# I3C0_WRAP_CORE_VBP_MST register map
Vendor: Texas Instruments
Peripheral module from a debugger description file (folder J7ES).
Registers are 32-bit, read-write, reset 0x0 unless marked. A register's access mark holds for its fields unless they carry their own. Offsets are as the file gives them; lines under a group give offsets from that group; [hi:lo] are bit positions; {n}, {i} and the like mark numbered series; 'fields as' and 'values as' point back to an identical list; <NAME> marks a mode.

## I3C0_WRAP_CORE_VBP_MST (part 1 of 2)
0x00 I3C_DEV_ID ro reset 0x5034 — This register holds the IP identifier.
  [15:0] DEV_ID — Unique IP identifier within IP portfolio
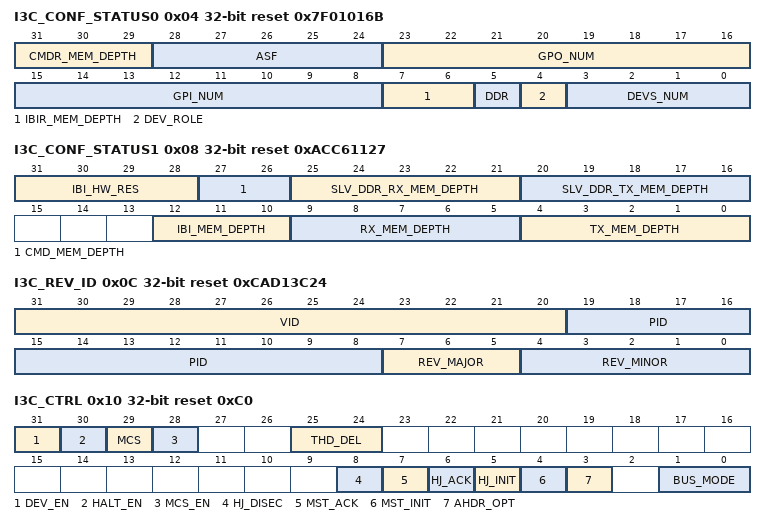
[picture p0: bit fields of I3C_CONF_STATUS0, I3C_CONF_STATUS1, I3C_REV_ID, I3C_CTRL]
0x04 I3C_CONF_STATUS0 ro reset 0x7F01016B — The read-only Configuration Status Register 0 indicates the hardware configuration options chosen for implementation of the I3C-Master.
  [31:29] CMDR_MEM_DEPTH — CMD Resp MEM depth coded into 3 bits
  [28:24] ASF — Indicates supported ASF checks
  [23:16] GPO_NUM — Returns the value of User GPO [1-126]
  [15:8] GPI_NUM — Returns the value of User GPI [1-126]
  [7:6] IBIR_MEM_DEPTH — IBI Resp MEM depth coded into 2 bits
  [5] DDR — Indicates if DDR is supported
  [4] DEV_ROLE — Returns status of Device Role [Main/Secondary Master]
  [3:0] DEVS_NUM — Returns the number of retaining registers for I3C Slave devices [Addresses and Characteristics], the max value is 11
0x08 I3C_CONF_STATUS1 ro reset 0xACC61127 — The read-only Configuration Status Register 1 indicates the hardware configuration options chosen for implementation of the I3C-Master.
  [31:28] IBI_HW_RES — IBI resources
  [27:26] CMD_MEM_DEPTH — CMD FIFO depth coded into 3 bits
  [25:21] SLV_DDR_RX_MEM_DEPTH — SLV DDR RX FIFO depth coded into 5 bits
  [20:16] SLV_DDR_TX_MEM_DEPTH — SLV DDR TX FIFO depth coded into 5 bits
  [12:10] IBI_MEM_DEPTH — IBI FIFO depth coded into 3 bits
  [9:5] RX_MEM_DEPTH — RX FIFO depth coded into 5 bits
  [4:0] TX_MEM_DEPTH — TX FIFO depth coded into 5 bits
0x0C I3C_REV_ID ro reset 0xCAD13C24 — This register gives an information about particular version of the IP.
  [31:20] VID — VENDOR_ID: IP vendor ID affected to IP [reset = 0xCAD]
  [19:8] PID — PRODUCT_ID: unique IP identifier within IP portfolio [reset = 0x13C]
  [7:5] REV_MAJOR — X: Major revision value
  [4:0] REV_MINOR — Y: Minor revision value
0x10 I3C_CTRL access per field reset 0xC0 — Control Register for I3C Master IP - register that provides main control and configuration options for the controller.
  [31] DEV_EN rw — When set HIGH the I3C-Master is enabled and it can initiates the I3C/I2C transactions Also write access to the following fields of various registers is forbidden : CTRLbus_mode CTRLahdr_opt CTRLhalt_en PRESCL_CTRL0i3c PRESCL_CTRL0i2c PRESCL_CTRL1od_low PRESCL_CTRL1pp_low When set LOW the I3C-Master is disabled and access to the key control fields that listed above is available If this bit is being set to 0 during ongoing transfer then it will wait until the transfer completion and then the controller will be disabled The actual status of the I3C Master IP is returned by MST_STATUS0idle bit of Status Register and this field should be checked before accessing key control fields
  [30] HALT_EN rw — Enable halt on abort behavior
  [29] MCS wo — Manual Command Start writing 1 starts execution of the commands currently in CMD Memories Self-cleared bit Relevant only if MCS_EN bit [CTRLmcs_en] set to 1, disregarded otherwise
  [28] MCS_EN rw — Manual Command Start Enable if set 1 the IP will wait with starting of command execution until MCS but [CTRLmcs] would be set 1 If set to 0, the IP will start execute commands automatically as soon as at lease one is present in the CMD MEM and the MCS [CTRLmcs] bit is disregarded
  [25:24] THD_DEL rw — Field that provides option to add data hold delay with respect to the SCL clock on which data on SDA is launched [applied only during actual Data transfer] 00 - adds delay of 3x sys_clock cycles, 01 - adds delay of 2x sys_clk clock cycles, 10 - adds delay of 1x sys_clk clock cycles, 11 - no delay [data is launched simultaneously with SCL clock edge]
  [8] HJ_DISEC rw — This bit controls the HW response for ACK'ed HJ request When set HIGH, then the DISEC CCC is used Otherwise, if set LOW the ENTDAA CCC is used This control bit is meaningful if hj_ack=1 and controller operates in Main Master configuration
  [7] MST_ACK rw — Specifies ACK response type for GETACCMST CCC, it can be either ACK response type [mst_ack = 1] or NACK response type [mst_ack = 0] This control bit is meaningful in Slave Mode only
  [6] HJ_ACK rw — Specifies ACK response type for HJ request, it can be either ACK response type [hj_ack = 1] or NACK response type [hj_ack = 0] For Secondary Master configuration, this bit tied off to 0
  [5] HJ_INIT wo — Initiate HJ request - applicable only for Secondary master in slave mode Self-cleared bit
  [4] MST_INIT wo — Initiate Mastership request - applicable only in slave mode When set in master mode this bit has no effect Self-cleared bit
  [3] AHDR_OPT rw — Enable[1]/Disable[0] the Address Header optimization If enabled, FW needs to restrict DAs to 0x 03 - 0x3F range
  [1:0] BUS_MODE rw — Bus Mode 00 : Pure Bus Mode 01 : Invalid Config 10 : Mixed Fast Bus Mode 11 : Mixed Slow/Limited Bus Mode
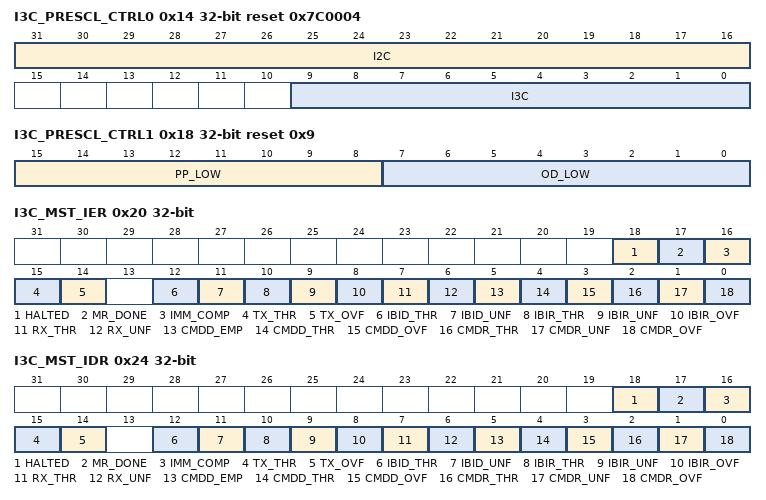
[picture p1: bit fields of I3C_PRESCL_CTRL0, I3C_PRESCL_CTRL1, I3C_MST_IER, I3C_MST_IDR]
0x14 I3C_PRESCL_CTRL0 access per field reset 0x7C0004 — Prescale settings for SDR/I2C modes
  [31:16] I2C rw — Prescaler value for I2C SCL clock generation It should be generated based on sys clock freq and should be 5x wrt to the slowest I2C device's SCL speed: presc_ctl_i2c [15:0] = sys_clk_freq / [i2c_freq * 5] - 1'b1 if presc_ctl_i2c [15:0]== 0 - no sys_clk division
  [9:0] I3C rw — Prescaler value for I3C Push-Pull SDR Mode SCL clock generation When the bus is configured in mixed fast mode, the resulting SCL frequency must be faster than 11MHz It should be generated based on sys clock freq and should be 4x wrt to the SDR SCL speed: presc_ctl_i3c [9:0] = [sys_clk_freq / sdr_freq * 4] - 1'b1 If sys_clk == 4*sdr_freq, presc_ctl_i3c [9:0] should be 0
0x18 I3C_PRESCL_CTRL1 reset 0x9 — Prescale settings related to Open Drain / Push Pull I3C timings
  [15:8] PP_LOW — Counter for low period of SCL clock for Push Pull in I3C When particular I3C device does not support Max SCL speed, low period stretching is required for PP as well Controller will determine that by inspecting BCR[0] bit When BCR[0] is 0, SCL waveform will have constant asymmetric ratio in Push-Pull mode as it will be calculated by 1/4 SCL * [pp_low + 2] The resolution used is 1/4 SDR SCL clock FW need to ensure 1/4 SCL * [pp_low + 2] &gt;= minimum low period duration for the particular device When BCR[0] is 1, PP timings will have 50/50 DC
  [7:0] OD_LOW — Counter for low period of SCL clock for Open Drain in I3C SCL waveform will have constant asymmetric ratio in OD as it will be calculated by 1/4 SCL * [od_low + 2] The resolution used is 1/4 SDR SCL clock FW need to ensure 1/4 SCL * [od_low + 2] &gt;= 160ns
0x20 I3C_MST_IER access not given — The write only Interrupt Enable Register is used to enable interrupts by setting bits in the read only Interrupt Mask Register - Master Mode (). See Interrupt Status Register - Master Mode () description for details on specific interrupt conditions. When any bit is written high, the corresponding interrupt is enabled. Writing a low to any bit has no effect.
  [18] HALTED — Controller in halted state (access W1C)
  [17] MR_DONE wo — Mastership handoff done Enable
  [16] IMM_COMP wo — Immediate Commmand Completed Enable
  [15] TX_THR wo — Tx Data Threshold Enable
  [14] TX_OVF wo — Tx Data MEM Underflow Enable
  [12] IBID_THR wo — IBI Data MEM threshold Enable
  [11] IBID_UNF wo — IBI Data MEM underflow Enable
  [10] IBIR_THR wo — IBI Response Queue threshold Enable
  [9] IBIR_UNF wo — IBI Response Queue underflow Enable
  [8] IBIR_OVF wo — IBI Response Queue onverflow Enable
  [7] RX_THR wo — Rx Data MEM threshold Enable
  [6] RX_UNF wo — Rx Data MEM underflow Enable
  [5] CMDD_EMP wo — Command Request Queue Empty Enable
  [4] CMDD_THR wo — Command Request Queue Threshold Enable
  [3] CMDD_OVF wo — Command Request Queue Overflow Enable
  [2] CMDR_THR wo — Command Response Queue Threshold Enable
  [1] CMDR_UNF wo — Command Response Queue Underflow Enable
  [0] CMDR_OVF wo — Command Response Queue Overflow Enable
0x24 I3C_MST_IDR access per field — The write only Interrupt Disable Register is used to disable interrupts by clearing the bits in the read only Interrupt Mask Register - Master Mode (). See Interrupt Status Register - Master Mode () description for details on specific interrupt conditions. When any bit is written high, the corresponding interrupt is disabled. Writing a low to any bit has no effect.
  [18] HALTED wo — Controller in halted state
  [17] MR_DONE wo — Mastership handoff done Disable
  [16] IMM_COMP wo — Immediate Commmand Completed Disable
  [15] TX_THR wo — Tx Data Threshold Disable
  [14] TX_OVF wo — Tx Data MEM Underflow Disable
  [12] IBID_THR wo — IBI Data MEM threshold Disable
  [11] IBID_UNF wo — IBI Data MEM underflow Disable
  [10] IBIR_THR wo — IBI Response Queue threshold Disable
  [9] IBIR_UNF wo — IBI Response Queue underflow Disable
  [8] IBIR_OVF wo — IBI Response Queue onverflow Disable
  [7] RX_THR wo — Rx Data MEM threshold Disable
  [6] RX_UNF wo — Rx Data MEM underflow Disable
  [5] CMDD_EMP wo — Command Request Queue Empty Disable
  [4] CMDD_THR wo — Command Request Queue Threshold Disable
  [3] CMDD_OVF wo — Command Request Queue Overflow Disable
  [2] CMDR_THR wo — Command Response Queue Threshold Disable
  [1] CMDR_UNF wo — Command Response Queue Underflow Disable
  [0] CMDR_OVF wo — Command Response Queue Overflow Disable
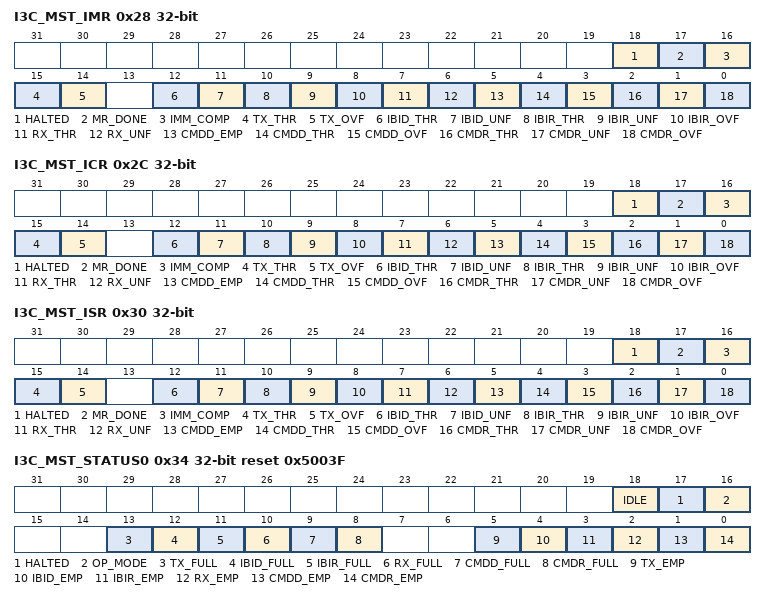
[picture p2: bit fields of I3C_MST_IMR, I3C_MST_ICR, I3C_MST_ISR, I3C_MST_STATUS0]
0x28 I3C_MST_IMR ro — This read only register, indicates the current state of the interrupts mask. See Interrupt Status Register - Master Mode () description for details on specific interrupt conditions. A high value indicates the interrupt is enabled to generate an interrupt. A low value indicates the interrupt is disabled from generating an interrupt (masked).
  [18] HALTED — Controller in halted state
  [17] MR_DONE — Mastership handoff done Mask
  [16] IMM_COMP — Immediate Commmand Completed Mask
  [15] TX_THR — Tx Data Threshold Mask
  [14] TX_OVF — Tx Data MEM Underflow Mask
  [12] IBID_THR — IBI Data MEM threshold Mask
  [11] IBID_UNF — IBI Data MEM underflow Mask
  [10] IBIR_THR — IBI Response Queue threshold Mask
  [9] IBIR_UNF — IBI Response Queue underflow Mask
  [8] IBIR_OVF — IBI Response Queue onverflow Mask
  [7] RX_THR — Rx Data MEM threshold Mask
  [6] RX_UNF — Rx Data MEM underflow Mask
  [5] CMDD_EMP — Command Request Queue Empty Mask
  [4] CMDD_THR — Command Request Queue Threshold Mask
  [3] CMDD_OVF — Command Request Queue Overflow Mask
  [2] CMDR_THR — Command Response Queue Threshold Mask
  [1] CMDR_UNF — Command Response Queue Underflow Mask
  [0] CMDR_OVF — Command Response Queue Overflow Mask
0x2C I3C_MST_ICR access per field — Interrupt Clear Register for Master Mode of the i3c_master controller. Write 1 to clear (change from 1 to 0) corresponding bit in . Writing 0 has no effect
  [18] HALTED wo — Controller is in halted state
  [17] MR_DONE wo — Mastership handoff done Mask
  [16] IMM_COMP wo — Immediate Commmand Completed Mask
  [15] TX_THR wo — Tx Data Threshold Mask
  [14] TX_OVF wo — Tx Data MEM Underflow Mask
  [12] IBID_THR wo — IBI Data MEM threshold Mask
  [11] IBID_UNF wo — IBI Data MEM underflow Mask
  [10] IBIR_THR wo — IBI Response Queue threshold Mask
  [9] IBIR_UNF wo — IBI Response Queue underflow Mask
  [8] IBIR_OVF wo — IBI Response Queue onverflow Mask
  [7] RX_THR wo — Rx Data MEM threshold Mask
  [6] RX_UNF wo — Rx Data MEM underflow Mask
  [5] CMDD_EMP wo — Command Request Queue Empty Mask
  [4] CMDD_THR wo — Command Request Queue Threshold Mask
  [3] CMDD_OVF wo — Command Request Queue Overflow Mask
  [2] CMDR_THR wo — Command Response Queue Threshold Mask
  [1] CMDR_UNF wo — Command Response Queue Underflow Mask
  [0] CMDR_OVF wo — Command Response Queue Overflow Mask
0x30 I3C_MST_ISR ro — Interrupt Status Register for Master Mode of the i3c_master controller
  [18] HALTED — Controller in Halted state
  [17] MR_DONE — Mastership handoff done
  [16] IMM_COMP — Immediate Commmand Completed
  [15] TX_THR — Tx Data Threshold
  [14] TX_OVF — Tx Data MEM overflow
  [12] IBID_THR — IBI Data MEM threshold
  [11] IBID_UNF — IBI Data MEM underflow
  [10] IBIR_THR — IBI Response Queue threshold
  [9] IBIR_UNF — IBI Response Queue underflow
  [8] IBIR_OVF — IBI Response Queue onverflow
  [7] RX_THR — Rx Data MEM threshold
  [6] RX_UNF — Rx Data MEM underflow
  [5] CMDD_EMP — Command Request Queue Empty
  [4] CMDD_THR — Command Request Queue Threshold
  [3] CMDD_OVF — Command Request Queue Overflow
  [2] CMDR_THR — Command Response Queue Threshold
  [1] CMDR_UNF — Command Response Queue Underflow
  [0] CMDR_OVF — Command Response Queue Overflow
0x34 I3C_MST_STATUS0 access not given reset 0x5003F — Status Register for I3C Master IP, meaningful only when controller operates in Master mode.
  [18] IDLE ro — Indicates when the core is IDLE and ready to accept new commands When CTRLdev_en is deasserted, FW should poll this reg in order to ensure that core completed its last command It is advisable to use this bit in order to ensure that currently the core is IDLE andI3C_CTRL register can be changed
  [17] HALTED — Core Halted This status bit will be asserted on the second abort has occurred during Read operation [if CTRLhalt_en=1] or in case of Rx DATA FIFO is full [regardless of CTRLhalt_en state] Writing 1 will unhalt the controllers core (access RW1C)
  [16] OP_MODE ro — Indicates current mode of the controller: 0 - Slave mode 1 - Master mode For Main Master configuration the reset value is 1 For Secondary Master configuration the reset value is 0 Set by HW
  [13] TX_FULL ro
  [12] IBID_FULL ro
  [11] IBIR_FULL ro — I3C_IBIR Full
  [10] RX_FULL ro
  [9] CMDD_FULL ro
  [8] CMDR_FULL ro — I3C_CMDR Full
  [5] TX_EMP ro — TX Empty
  [4] IBID_EMP ro — IBID Empty
  [3] IBIR_EMP ro — I3C_IBIR Empty
  [2] RX_EMP ro — RX Empty
  [1] CMDD_EMP ro — CMDD Empty
  [0] CMDR_EMP ro — I3C_CMDR Empty
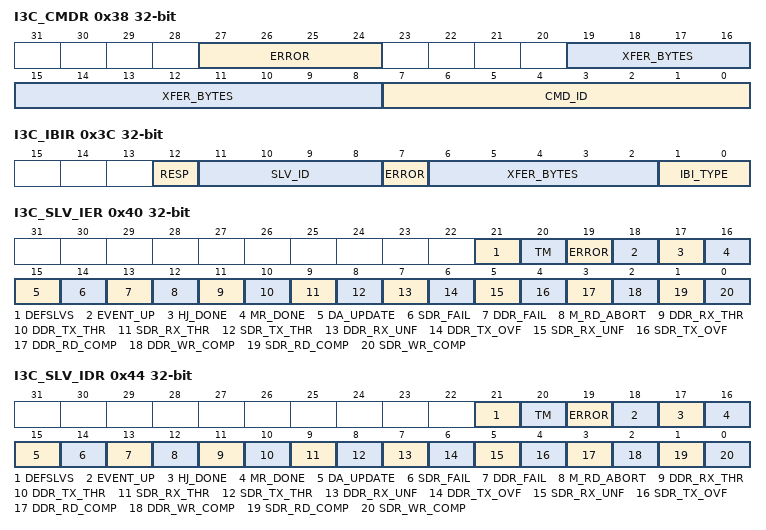
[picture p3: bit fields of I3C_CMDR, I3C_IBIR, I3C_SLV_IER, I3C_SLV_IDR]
0x38 I3C_CMDR ro — Stores status on completion of each command, works on FIFO-basis.
  [27:24] ERROR — This field contains the code of an error that has occured during the last transaction
  [19:8] XFER_BYTES — The number of transferred bytes [SDR] or transferred words [DDR] during the last command Will be set correctly for CCC commands as well even for those without payload [to zero value]
  [7:0] CMD_ID — CMD_ID - command identifier
0x3C I3C_IBIR ro — Stores status of SIR on its completion, works on FIFO-basis.
  [12] RESP — If HIGH IBI has been ACKed, NACK response otherwise
  [11:8] SLV_ID — ID of a Slave that has issued an IBI request
  [7] ERROR — Set to 1 if IBI Data FIFO overflow has occured during the transaction
  [6:2] XFER_BYTES — Number of received DATA bytes
  [1:0] IBI_TYPE — This field contains the type of an IBI
0x40 I3C_SLV_IER wo — The write only Interrupt Enable Register is used to enable interrupts by setting bits in the read only Interrupt Mask Register - Slave Mode (). See Interrupt Status Register - Slave Mode () description for details on specific interrupt conditions. When any bit is written high, the corresponding interrupt is enabled. Writing a low to any bit has no effect.
  [21] DEFSLVS — DEFSLVS interrupt Enable
  [20] TM — TM interrupt Enable
  [19] ERROR — ERROR interrupt Enable
  [18] EVENT_UP — EVENT_UP interrupt Enable
  [17] HJ_DONE — HJ_DONE interrupt Enable
  [16] MR_DONE — MR_DONE interrupt Enable
  [15] DA_UPDATE — DA_UPDATE interrupt Enable
  [14] SDR_FAIL — SDR_FAIL interrupt Enable
  [13] DDR_FAIL — DDR_FAIL interrupt Enable
  [12] M_RD_ABORT — M_RD_ABORT interrupt Enable
  [11] DDR_RX_THR — DDR_RX_THR interrupt Enable
  [10] DDR_TX_THR — DDR_TX_THR interrupt Enable
  [9] SDR_RX_THR — SDR_RX_THR interrupt Enable
  [8] SDR_TX_THR — SLV_SDR_TX_THR interrupt Enable
  [7] DDR_RX_UNF — DDR_RX_UNF interrupt Enable
  [6] DDR_TX_OVF — DDR_TX_OVF interrupt Enable
  [5] SDR_RX_UNF — SDR_RX_UNF interrupt Enable
  [4] SDR_TX_OVF — SDR_TX_OVF interrupt Enable
  [3] DDR_RD_COMP — DDR_RD_COMP interrupt Enable
  [2] DDR_WR_COMP — DDR_WR_COMP interrupt Enable
  [1] SDR_RD_COMP — SDR_RD_COMP interrupt Enable
  [0] SDR_WR_COMP — SDR_WR_COMP interrupt Enable
0x44 I3C_SLV_IDR wo — The write only Interrupt Disable Register is used to disable interrupts by clearing the bits in the read only Interrupt Mask Register - Slave Mode (). See Interrupt Status Register - Slave Mode () description for details on specific interrupt conditions. When any bit is written high, the corresponding interrupt is disabled. Writing a low to any bit has no effect.
  [21] DEFSLVS — DEFSLVS interrupt Disable
  [20] TM — TM interrupt Disable
  [19] ERROR — ERROR interrupt Disable
  [18] EVENT_UP — EVENT_UP interrupt Disable
  [17] HJ_DONE — HJ_DONE interrupt Disable
  [16] MR_DONE — MR_DONE interrupt Disable
  [15] DA_UPDATE — DA_UPDATE interrupt Disable
  [14] SDR_FAIL — SDR_FAIL interrupt Disable
  [13] DDR_FAIL — DDR_FAIL interrupt Disable
  [12] M_RD_ABORT — M_RD_ABORT interrupt Disable
  [11] DDR_RX_THR — DDR_RX_THR interrupt Disable
  [10] DDR_TX_THR — DDR_TX_THR interrupt Disable
  [9] SDR_RX_THR — SDR_RX_THR interrupt Disable
  [8] SDR_TX_THR — SDR_TX_THR interrupt Disable
  [7] DDR_RX_UNF — DDR_RX_UNF interrupt Disable
  [6] DDR_TX_OVF — DDR_TX_OVF interrupt Disable
  [5] SDR_RX_UNF — SDR_RX_UNF interrupt Disable
  [4] SDR_TX_OVF — SDR_TX_OVF interrupt Disable
  [3] DDR_RD_COMP — DDR_RD_COMP interrupt Disable
  [2] DDR_WR_COMP — DDR_WR_COMP interrupt Disable
  [1] SDR_RD_COMP — SDR_RD_COMP interrupt Disable
  [0] SDR_WR_COMP — SDR_WR_COMP interrupt Disable
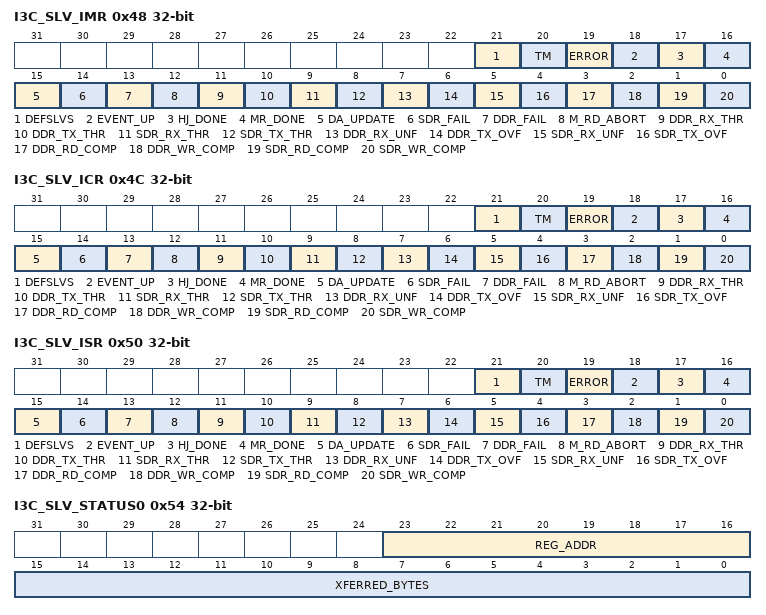
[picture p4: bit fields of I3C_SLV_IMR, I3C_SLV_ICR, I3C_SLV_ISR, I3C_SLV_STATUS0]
0x48 I3C_SLV_IMR ro — This read only register, indicates the current state of the interrupts mask. See Interrupt Status Register - Slave Mode () description for details on specific interrupt conditions. A high value indicates the interrupt is enabled to generate an interrupt. A low value indicates the interrupt is disabled from generating an interrupt (masked).
  [21] DEFSLVS — DEFSLVS interrupt Mask
  [20] TM — TM interrupt Mask
  [19] ERROR — ERROR interrupt Mask
  [18] EVENT_UP — EVENT_UP interrupt Mask
  [17] HJ_DONE — HJ_DONE interrupt Mask
  [16] MR_DONE — MR_DONE interrupt Mask
  [15] DA_UPDATE — DA_UPDATE interrupt Mask
  [14] SDR_FAIL — SDR_FAIL interrupt Mask
  [13] DDR_FAIL — DDR_FAIL interrupt Mask
  [12] M_RD_ABORT — M_RD_ABORT interrupt Mask
  [11] DDR_RX_THR — DDR_RX_THR interrupt Mask
  [10] DDR_TX_THR — DDR_TX_THR interrupt Mask
  [9] SDR_RX_THR — SDR_RX_THR interrupt Mask
  [8] SDR_TX_THR — SDR_TX_THR interrupt Mask
  [7] DDR_RX_UNF — DDR_RX_UNF interrupt Mask
  [6] DDR_TX_OVF — DDR_TX_OVF interrupt Mask
  [5] SDR_RX_UNF — SDR_RX_UNF interrupt Mask
  [4] SDR_TX_OVF — SDR_TX_OVF interrupt Mask
  [3] DDR_RD_COMP — DDR_RD_COMP interrupt Mask
  [2] DDR_WR_COMP — DDR_WR_COMP interrupt Mask
  [1] SDR_RD_COMP — SDR_RD_COMP interrupt Mask
  [0] SDR_WR_COMP — SDR_WR_COMP interrupt Mask
0x4C I3C_SLV_ICR wo — Interrupt Clear Register for Slave Mode of the i3c_master controller. Write 1 to clear (change from 1 to 0) corresponding bit in . Writing 0 has no effect
  [21] DEFSLVS — DEFSLVS interrupt Clear
  [20] TM — TM interrupt Clear
  [19] ERROR — ERROR interrupt Clear
  [18] EVENT_UP — EVENT_UP interrupt Clear
  [17] HJ_DONE — HJ_DONE interrupt Clear
  [16] MR_DONE — MR_DONE interrupt Clear
  [15] DA_UPDATE — DA_UPDATE interrupt Clear
  [14] SDR_FAIL — SDR_FAIL interrupt Clear
  [13] DDR_FAIL — DDR_FAIL interrupt Clear
  [12] M_RD_ABORT — M_RD_ABORT interrupt Clear
  [11] DDR_RX_THR — DDR_RX_THR interrupt Clear
  [10] DDR_TX_THR — DDR_TX_THR interrupt Clear
  [9] SDR_RX_THR — SDR_RX_THR interrupt Clear
  [8] SDR_TX_THR — SDR_TX_THR interrupt Clear
  [7] DDR_RX_UNF — DDR_RX_UNF interrupt Clear
  [6] DDR_TX_OVF — DDR_TX_OVF interrupt Clear
  [5] SDR_RX_UNF — SDR_RX_UNF interrupt Clear
  [4] SDR_TX_OVF — SDR_TX_OVF interrupt Clear
  [3] DDR_RD_COMP — DDR_RD_COMP interrupt Clear
  [2] DDR_WR_COMP — DDR_WR_COMP interrupt Clear
  [1] SDR_RD_COMP — SDR_RD_COMP interrupt Clear
  [0] SDR_WR_COMP — SDR_WR_COMP interrupt Clear
0x50 I3C_SLV_ISR ro — Interrupt Status Register for Slave Mode of the i3c_master controller
  [21] DEFSLVS — This interrupt is triggered whenever I3C-Slave DEFSLVS CCC command is received
  [20] TM — This interrupt is triggered whenever I3C-Slave is not in Test Mode and ENTTM CCC command with byte value of 0x01 [general Test Mode] is received
  [19] ERROR — This event is triggered whenever SDR Error is detected - applicable for S0, S1, S2, S4 and S5 Errors from MIPI spec
  [18] EVENT_UP — This event is triggered whenever DISEC CCC or ENEC CCC is received
  [17] HJ_DONE — This event is triggered whenever Hot-Join request is completed
  [16] MR_DONE — This event is triggered whenever Mastership Request is completed
  [15] DA_UPDATE — This event is triggered whenever Dynamic Address of the device has been updated
  [14] SDR_FAIL — This event is triggered whenever fail event during SDR transfer is detected [applicable for Private Write transfers only]
  [13] DDR_FAIL — This event is triggered whenever fail event during DDR transfer is detected
  [12] M_RD_ABORT — Read Transfer Aborted by Master
  [11] DDR_RX_THR — This event is triggered whenever threshold level for DDR Rx DATA Buffer is reached
  [10] DDR_TX_THR — This event is triggered whenever threshold level for DDR Tx DATA Buffer is reached
  [9] SDR_RX_THR — Rx DATA Buffer Threshold It is set when the number of bytes in the Rx DATA Buffer reaches value programmed in TX_RX_THR_CTRLrx_thr field
  [8] SDR_TX_THR — Tx DATA Buffer Threshold It is set when the number of bytes in the Tx DATA Buffer reaches value programmed in TX_RX_THR_CTRLtx_thr field
  [7] DDR_RX_UNF — Set if the host attempts to read from the DDR_RX_FIFO register when there is no more data
  [6] DDR_TX_OVF — Set if the host attempts to write to DDR_TX_FIFO register more times than the FIFO depth
  [5] SDR_RX_UNF — Rx DATA Buffer Underflow Set if the host attempts to read from the empty Rx DATA Buffer
  [4] SDR_TX_OVF — Tx DATA Buffer Overflow Set if host attempts to write to Tx DATA Buffer which is already full
  [3] DDR_RD_COMP — This bit is set whenever the Slave terminates the DDR Read transfer
  [2] DDR_WR_COMP — This bit is set whenever the Master terminates the DDR Write transfer
  [1] SDR_RD_COMP — This bit is set whenever the Slave terminates the SDR Private Read transfer
  [0] SDR_WR_COMP — This bit is set whenever the Master terminates the SDR Private Write transfer
0x54 I3C_SLV_STATUS0 ro — The read only Status 0 register () is provided to enable the continuous monitoring of the raw unmasked status information of the I3C-Master operating in Slave mode.
  [23:16] REG_ADDR — Private Read/Write Address
  [15:0] XFERRED_BYTES — Number of transferred bytes in SDR transactions
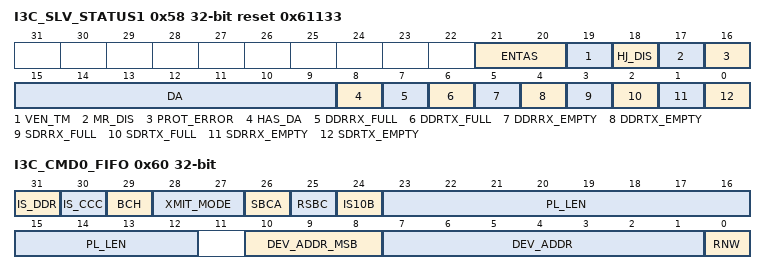
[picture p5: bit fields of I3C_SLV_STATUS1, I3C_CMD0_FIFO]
0x58 I3C_SLV_STATUS1 ro reset 0x61133 — The read only Status 1 register () is provided to enable the continuous monitoring of the raw unmasked status information of the I3C-Master operating in Slave mode.
  [21:20] ENTAS — Bits that indicate current Activity State It is updated based on ENTASx CCC [broadcast or direct], by default is set to 2'b00
  [19] VEN_TM — Vendor Test Mode This bit is set whenever ENTTM CCC is received with value of 0x01 It remains HIGH until reception of another ENTTM CCC with different value
  [18] HJ_DIS — Hot-Join Disabled This bit is set whenever HJ request is disabled by Current I3C-Master using DISEC CCC
  [17] MR_DIS — This bit is set whenever MR request is disabled by Current I3C-Master using DISEC CCC
  [16] PROT_ERROR — Protocol Error Condition Indicator This bit is set whenever SDR error condition is detected by I3C-Master operating in Slave mode It remains High until detection of recovery pattern
  [15:9] DA — Slave Dynamic Address
  [8] HAS_DA — This bit is set whenever Slave has Dynamic Address assigned
  [7] DDRRX_FULL — This bit is set wheneverI3C_SLV_DDR_RX_FIFO is full
  [6] DDRTX_FULL — This bit is set wheneverI3C_SLV_DDR_TX_FIFO is full
  [5] DDRRX_EMPTY — This bit is set wheneverI3C_SLV_DDR_RX_FIFO is empty
  [4] DDRTX_EMPTY — This bit is set wheneverI3C_SLV_DDR_TX_FIFO is empty
  [3] SDRRX_FULL — This bit is set whenever SDR_RX_FIFO is full
  [2] SDRTX_FULL — This bit is set whenever SDR_TX_FIFO is full
  [1] SDRRX_EMPTY — This bit is set whenever SDR_RX_FIFO is empty
  [0] SDRTX_EMPTY — This bit is set whenever SDR_TX_FIFO is empty
0x60 I3C_CMD0_FIFO wo — Command0 FIFO. When implemented, the commands will be executed sequentially in order of arrival from the FW.
  [31] IS_DDR — IS_DDR - DDR command Enables DDR mode of transfer 0 - SDR mode 1 - DDR mode, note that ENTHDR-DDR CCC should precede any commands with DDR mode enabled
  [30] IS_CCC — IsCCC Denotes whether it is a CCC or generic command 0 - generic command 1 - CCC command
  [29] BCH — BCH - Broadcast Header Defines whether command will includes broadcast address header [0x7E] or not Implicitly set for CCC commands 0 - broadcast header disabled 1 - broadcast header enabled
  [28:27] XMIT_MODE — Defines transfer modes for I3C private read/write commands [not CCC], the following options are available: 00 - single CSR address Send one single slave CSR address followed by data bytes only Expecting slave will make self-increment of the address for each data byte or will have payload buffer implemented 01 - multi byte incrementing CSR address, each data byte followed by repeated start condition and the slave's CSR address incremented explicitly 10 - multi byte static CSR address, each data byte followed by repeat start condition and the slave's CSR address unchanged 11 - No CSR ADDR [NCA], CCC/CSR ADDR0 filed is not used First data byte after the slave address is a payload
  [26] SBCA — SBCA - Sixteen Bits CSR Addressing Defines the CSR addressing mode for I3C private commands only 0 - normal CSR addressing mode [8-bit] - ADDR0_ 7 - ADDR0_0 1 - extended CSR addressing mode [16-bit] - ADDR0_ 7 - ADDR0_0 and ADDR1_ 7 - ADDR1_0
  [25] RSBC — RSBC - Repeated Start Between Commands When this bit is set then between commands he repeated start condition is issued instead stop condition It is only applicable when there is more than one command is in the command queue and next command is for Slave device of same type The stop condition will be generated regardless of RSCB bit value for the following scenarios: - current command is the last command in the command queue - next command has invalid DA/SA - immediate command comes through
  [24] IS10B — Is10B - Normal/Extended Address Defines the addressing mode, applicable only for legacy I2C messaging 0 - normal addressing mode [7-bit] - ID 6-ID0 1 - extended addressing mode [10-bit] - ID10B 2-ID10B0 and ID 6-ID0
  [23:12] PL_LEN — PL_LEN - Payload Length The number of bytes to be sent for particular CCC or generic R/Q command Supports up to 4095 bytes
  [10:8] DEV_ADDR_MSB — DEV_ADDR_MSB - legacy I2C Extended Address The 3 MSB bits of legacy I2C 10-bit address Applicable only if Is_10B is set for I2C legacy transfers
  [7:1] DEV_ADDR — DEV_ADDR - Static/Dynamic slave Address Correspond to a given slave Dynamic Address and Static Address For CCC is applicable only when it is direct CCC command For broadcast CCC this field is ignored
  [0] RNW — RnW - Read no Write Defines the direction of transfer, for broadcast CCC this field is ignored 0 - Write Transfer 1 - Read Transfer
